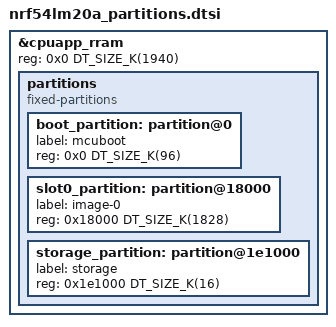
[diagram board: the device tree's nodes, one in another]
/delete-node/ &boot_partition;
/delete-node/ &slot0_partition;
/delete-node/ &slot1_partition;
/delete-node/ &storage_partition;

&cpuapp_rram {
	reg = <0x0 DT_SIZE_K(1940)>;

	partitions {
		compatible = "fixed-partitions";
		#address-cells = <1>;
		#size-cells = <1>;

		boot_partition: partition@0 {
			label = "mcuboot";
			reg = <0x0 DT_SIZE_K(96)>;
		};

		slot0_partition: partition@18000 {
			label = "image-0";
			reg = <0x18000 DT_SIZE_K(1828)>;
		};

		storage_partition: partition@1e1000 {
			label = "storage";
			reg = <0x1e1000 DT_SIZE_K(16)>;
		};
	};
};
